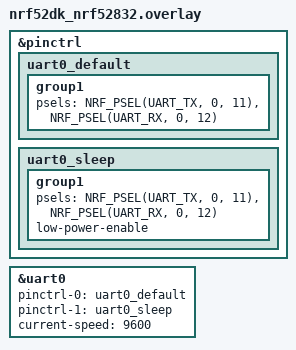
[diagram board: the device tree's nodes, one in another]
&pinctrl {
    uart0_default: uart0_default {
        group1 {
            psels = <NRF_PSEL(UART_TX, 0, 11)>,  /* Change '6' to your new TX pin */
                    <NRF_PSEL(UART_RX, 0, 12)>;  /* Change '8' to your new RX pin */
        };
    };

    uart0_sleep: uart0_sleep {
        group1 {
            psels = <NRF_PSEL(UART_TX, 0, 11)>,
                    <NRF_PSEL(UART_RX, 0, 12)>;
            low-power-enable;
        };
    };
};

&uart0 {
    status = "okay";
    pinctrl-0 = <&uart0_default>;
    pinctrl-1 = <&uart0_sleep>;
    pinctrl-names = "default", "sleep";
    current-speed = <9600>; /* You can set the default baud rate here too */
};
